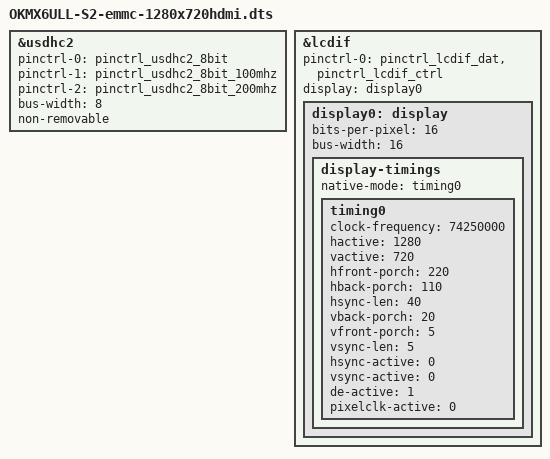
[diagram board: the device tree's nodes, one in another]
/*
 * Copyright (C) 2016 Freescale Semiconductor, Inc.
 *
 * This program is free software; you can redistribute it and/or modify
 * it under the terms of the GNU General Public License version 2 as
 * published by the Free Software Foundation.
 */

#include "imx6ull-14x14-evk.dts"

&usdhc2 {
	pinctrl-names = "default", "state_100mhz", "state_200mhz";
	pinctrl-0 = <&pinctrl_usdhc2_8bit>;
	pinctrl-1 = <&pinctrl_usdhc2_8bit_100mhz>;
	pinctrl-2 = <&pinctrl_usdhc2_8bit_200mhz>;
	bus-width = <8>;
	non-removable;
	status = "okay";
};
&lcdif {
	pinctrl-names = "default";
	pinctrl-0 = <&pinctrl_lcdif_dat
		     &pinctrl_lcdif_ctrl
		    /* &pinctrl_lcdif_reset*/>;
	display = <&display0>;
	status = "okay";

	display0: display {
		bits-per-pixel = <16>;
		bus-width = <16>;

		display-timings {
			native-mode = <&timing0>;
			timing0: timing0 {
			clock-frequency = <74250000>;
			hactive = <1280>;
			vactive = <720>;
			hfront-porch = <220>;
			hback-porch = <110>;
			hsync-len = <40>;
			vback-porch = <20>;
			vfront-porch = <5>;
			vsync-len = <5>;

			hsync-active = <0>;
			vsync-active = <0>;
			de-active = <1>;
			pixelclk-active = <0>;
			};
		};
	};
};

